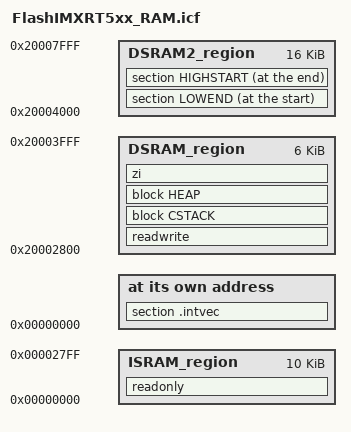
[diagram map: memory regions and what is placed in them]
/*###ICF### Section handled by ICF editor, don't touch! ****/
/*-Editor annotation file-*/
/* IcfEditorFile="$TOOLKIT_DIR$\config\ide\IcfEditor\cortex_v1_0.xml" */
/*-Specials-*/
define symbol __ICFEDIT_intvec_start__ = 0x00000000;
/*-Memory Regions-*/

/*-Sizes-*/
define symbol __ICFEDIT_size_cstack__   = 0x400;
define symbol __ICFEDIT_size_heap__     = 0x100;
/**** End of ICF editor section. ###ICF###*/

define symbol __region_ISRAM_start__   = 0x00000000;
define symbol __region_ISRAM_end__     = 0x000027FF;

define symbol __region_DSRAM_start__   = 0x20002800;
define symbol __region_DSRAM_end__     = 0x20003FFF;

define symbol __region_DSRAM2_start__   = 0x20004000;
define symbol __region_DSRAM2_end__     = 0x20007FFF;

define memory mem with size = 4G;
define region ISRAM_region = mem:[from __region_ISRAM_start__ to __region_ISRAM_end__];
define region DSRAM_region = mem:[from __region_DSRAM_start__ to __region_DSRAM_end__];
define region DSRAM2_region  = mem:[from __region_DSRAM2_start__   to __region_DSRAM2_end__];

define block CSTACK    with alignment = 8, size = __ICFEDIT_size_cstack__   { };
define block HEAP      with alignment = 8, size = __ICFEDIT_size_heap__     { };

/*do not initialize { zi };*/

place at address mem:__ICFEDIT_intvec_start__ { section .intvec };

place in ISRAM_region { readonly };
place in DSRAM_region { readwrite, block CSTACK, block HEAP };
place in DSRAM_region { zi };

/* Looks like the following definitions determine the location and size of
   the flash loader buffer.
*/
place at start of DSRAM2_region {section LOWEND};
place at end of DSRAM2_region   {section HIGHSTART};
